# CY8C5888LTI_LP097 register map
File version: 0.1
CY8C58LP
Registers are 8-bit, read-write, no defined reset value unless marked. A register's access mark holds for its fields unless they carry their own. Offsets are from the block's base; lines under a group give offsets from that group; [hi:lo] are bit positions; {n}, {i} and the like mark numbered series; 'fields as' and 'values as' point back to an identical list; <NAME> marks a mode.

## Memory map
0x00000000 ADC_SAR_Seq_2_SAR — SAR ADC
0x00000000 EZI2C_1
0x00000000 UART_1 — UART
0x00000000 ADC_SAR_Seq_1_SAR — SAR ADC

## ADC_SAR_Seq_2_SAR — SAR ADC
Base 0x00000000
0x40004616 SAR_TR0 — SAR trim register
{0x40005908+i} SAR_CSR{i} (i=0..6) — SAR status and control register {i}
0x40005B28 SAR_SW0 — SAR Analog Routing Register 0
{0x40005B28+i} SAR_SW{i} (i=2..4) — SAR Analog Routing Register {i}
0x40005B2E SAR_SW6 — SAR Analog Routing Register 6
0x40005B2F SAR_CLK — SAR Clock Selection Register
0x40005BA2 SAR_WRK 16-bit — SAR working register

## UART_1 — UART
Base 0x00000000
0x4000644A TX_UART_1_TX_DATA — TX Data Register
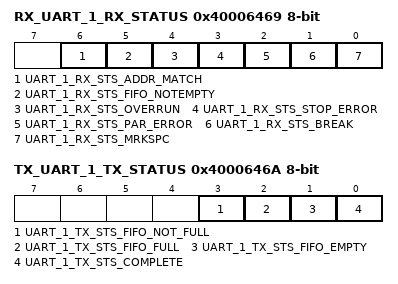
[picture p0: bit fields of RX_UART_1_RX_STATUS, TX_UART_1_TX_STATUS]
0x40006469 RX_UART_1_RX_STATUS — RX status register
  [6] UART_1_RX_STS_ADDR_MATCH ro, [5] UART_1_RX_STS_FIFO_NOTEMPTY ro, [4] UART_1_RX_STS_OVERRUN ro, [3] UART_1_RX_STS_STOP_ERROR ro, [2] UART_1_RX_STS_PAR_ERROR ro, [1] UART_1_RX_STS_BREAK ro, [0] UART_1_RX_STS_MRKSPC ro
0x4000646A TX_UART_1_TX_STATUS — TX status register
  [3] UART_1_TX_STS_FIFO_NOT_FULL ro, [2] UART_1_TX_STS_FIFO_FULL ro, [1] UART_1_TX_STS_FIFO_EMPTY ro, [0] UART_1_TX_STS_COMPLETE ro
0x40006529 RX_UART_1_RX_ADDRESS1 — RX Address1 Register
0x40006539 RX_UART_1_RX_ADDRESS2 — RX Address2 Register
0x40006549 RX_UART_1_RX_DATA — RX Data Register

## ADC_SAR_Seq_1_SAR — SAR ADC
Base 0x00000000
0x40004614 SAR_TR0 — SAR trim register
{0x40005900+i} SAR_CSR{i} (i=0..6) — SAR status and control register {i}
0x40005B20 SAR_SW0 — SAR Analog Routing Register 0
{0x40005B20+i} SAR_SW{i} (i=2..4) — SAR Analog Routing Register {i}
0x40005B26 SAR_SW6 — SAR Analog Routing Register 6
0x40005B27 SAR_CLK — SAR Clock Selection Register
0x40005BA0 SAR_WRK 16-bit — SAR working register
